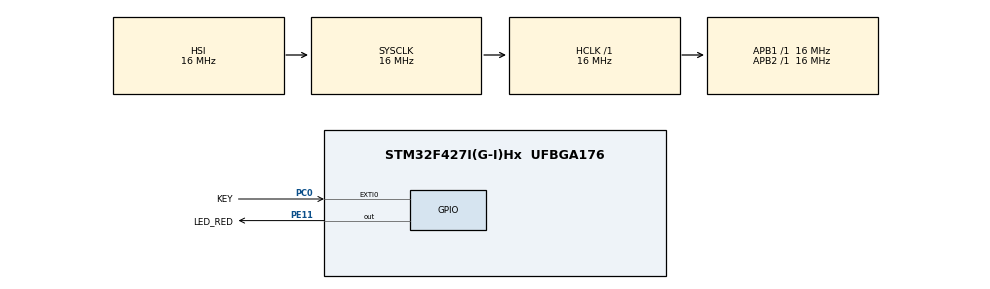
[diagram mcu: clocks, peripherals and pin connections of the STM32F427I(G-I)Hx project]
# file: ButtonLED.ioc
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Mcu.Family=STM32F4
Mcu.Name=STM32F427I(G-I)Hx
Mcu.Package=UFBGA176
NVIC.EXTI0_IRQn=true\:0\:0\:false\:false\:true\:true\:true\:true
NVIC.PriorityGroup=NVIC_PRIORITYGROUP_4
PA13.Mode=Serial_Wire
PA13.Signal=SYS_JTMS-SWDIO
PA14.Mode=Serial_Wire
PA14.Signal=SYS_JTCK-SWCLK
PC0.GPIO_Label=KEY
PC0.GPIO_ModeDefaultEXTI=GPIO_MODE_IT_RISING_FALLING
PC0.GPIO_PuPd=GPIO_PULLUP
PC0.Signal=GPXTI0
PE11.GPIO_Label=LED_RED
PE11.PinState=GPIO_PIN_SET
PE11.Signal=GPIO_Output
PH0/OSC_IN.Mode=HSE-External-Oscillator
PH0/OSC_IN.Signal=RCC_OSC_IN
PH1/OSC_OUT.Mode=HSE-External-Oscillator
PH1/OSC_OUT.Signal=RCC_OSC_OUT
ProjectManager.HeapSize=0x200
ProjectManager.StackSize=0x400
ProjectManager.TargetToolchain=MDK-ARM V5.32
RCC.AHBFreq_Value=16000000
RCC.APB1Freq_Value=16000000
RCC.APB2Freq_Value=16000000
RCC.CortexFreq_Value=16000000
RCC.HSE_VALUE=25000000
RCC.HSI_VALUE=16000000
RCC.LSE_VALUE=32768
RCC.SYSCLKFreq_VALUE=16000000
RCC.VCOOutputFreq_Value=192000000
board=custom

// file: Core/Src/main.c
/* USER CODE BEGIN Header */
/**
  ******************************************************************************
  * @file           : main.c
  * @brief          : Main program body
  ******************************************************************************
  * @attention
  *
  * Copyright (c) 2023 STMicroelectronics.
  * All rights reserved.
  *
  * This software is licensed under terms that can be found in the LICENSE file
  * in the root directory of this software component.
  * If no LICENSE file comes with this software, it is provided AS-IS.
  *
  ******************************************************************************
  */
/* USER CODE END Header */
#include "main.h"
#include "gpio.h"

/* USER CODE BEGIN PV */
uint8_t exit_flag=1;
uint8_t rising_falling_flag;
/* USER CODE END PV */

void SystemClock_Config(void);
/* USER CODE BEGIN PFP */
void HAL_GPIO_EXTI_Callback(uint16_t GPIO_Pin);
/* USER CODE END PFP */

int main(void)
{

  /* MCU Configuration--------------------------------------------------------*/

  /* Reset of all peripherals, Initializes the Flash interface and the Systick. */
  HAL_Init();

  /* Configure the system clock */
  SystemClock_Config();

  /* Initialize all configured peripherals */
  MX_GPIO_Init();

  /* Infinite loop */
  while (1)
  {

    /* USER CODE BEGIN 3 */
      if(!exit_flag){
          if(rising_falling_flag==GPIO_PIN_SET){
             HAL_Delay(20);
             rising_falling_flag=HAL_GPIO_ReadPin(GPIOC,GPIO_PIN_0);
             if(rising_falling_flag==GPIO_PIN_SET){
                 HAL_GPIO_WritePin(LED_RED_GPIO_Port,LED_RED_Pin,GPIO_PIN_RESET);
             }
         }
          else if(rising_falling_flag==GPIO_PIN_RESET){
             HAL_Delay(20);
             rising_falling_flag=HAL_GPIO_ReadPin(GPIOC,GPIO_PIN_0);
             if(rising_falling_flag==GPIO_PIN_RESET){
                 HAL_GPIO_WritePin(LED_RED_GPIO_Port,LED_RED_Pin,GPIO_PIN_SET);
             }
          }
          exit_flag=1;
      }
  }
  /* USER CODE END 3 */
}

void SystemClock_Config(void)
{
  RCC_OscInitTypeDef RCC_OscInitStruct = {0};
  RCC_ClkInitTypeDef RCC_ClkInitStruct = {0};

  /** Configure the main internal regulator output voltage
  */
  __HAL_RCC_PWR_CLK_ENABLE();
  __HAL_PWR_VOLTAGESCALING_CONFIG(PWR_REGULATOR_VOLTAGE_SCALE3);

  /** Initializes the RCC Oscillators according to the specified parameters
  * in the RCC_OscInitTypeDef structure.
  */
  RCC_OscInitStruct.OscillatorType = RCC_OSCILLATORTYPE_HSI;
  RCC_OscInitStruct.HSIState = RCC_HSI_ON;
  RCC_OscInitStruct.HSICalibrationValue = RCC_HSICALIBRATION_DEFAULT;
  RCC_OscInitStruct.PLL.PLLState = RCC_PLL_NONE;
  if (HAL_RCC_OscConfig(&RCC_OscInitStruct) != HAL_OK)
  {
    Error_Handler();
  }

  /** Initializes the CPU, AHB and APB buses clocks
  */
  RCC_ClkInitStruct.ClockType = RCC_CLOCKTYPE_HCLK|RCC_CLOCKTYPE_SYSCLK
                              |RCC_CLOCKTYPE_PCLK1|RCC_CLOCKTYPE_PCLK2;
  RCC_ClkInitStruct.SYSCLKSource = RCC_SYSCLKSOURCE_HSI;
  RCC_ClkInitStruct.AHBCLKDivider = RCC_SYSCLK_DIV1;
  RCC_ClkInitStruct.APB1CLKDivider = RCC_HCLK_DIV1;
  RCC_ClkInitStruct.APB2CLKDivider = RCC_HCLK_DIV1;

  if (HAL_RCC_ClockConfig(&RCC_ClkInitStruct, FLASH_LATENCY_0) != HAL_OK)
  {
    Error_Handler();
  }
}

/* USER CODE BEGIN 4 */

void HAL_GPIO_EXTI_Callback(uint16_t GPIO_Pin)
{
    if(exit_flag){
        rising_falling_flag=HAL_GPIO_ReadPin(GPIOC,GPIO_PIN_0);
        exit_flag=0;
    }
    else{
        return;
    }
}

/* USER CODE END 4 */

void Error_Handler(void)
{
  __disable_irq();
  while (1)
  {
  }
}
